AUTOSAR XML (schema 4-2-2)
package /ComponentTypes
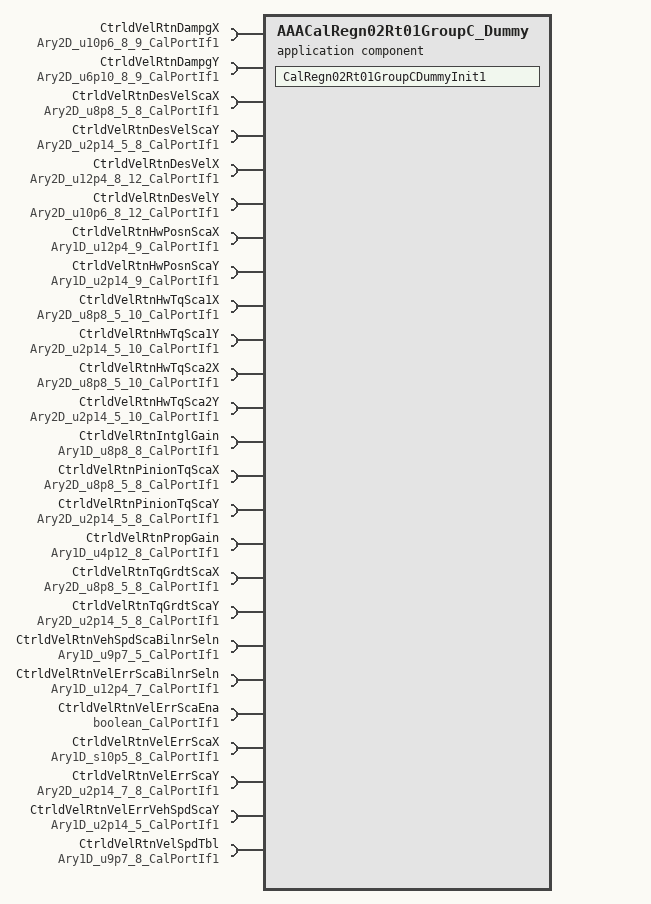
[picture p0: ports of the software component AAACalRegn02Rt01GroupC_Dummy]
  application sw component type AAACalRegn02Rt01GroupC_Dummy
    25 x require port:
      CtrldVelRtnDampgX: parameter-require-com-spec{init-value=[[0, 8960, 10560, 12160, 13760, 15360, 18560, 21760, 24960], [0, 8960, 10560, 12160, 13760, 15360, 18560, 21760, 24960], [0, 8960, 10560, 12160, 13760, 15360, 18560, 21760, 24960], [0, 8960, 10560, 12160, 13760, 15360, 18560, 21760, 24960], [0, 8960, 10560, 12160, 13760, 15360, 18560, 21760, 24960], [0, 16000, 17600, 19200, 20800, 22400, 25600, 28800, 32000], [0, 20608, 22208, 23808, 25408, 27008, 30208, 33408, 36608], [0, 26112, 27712, 29312, 30912, 32512, 35712, 38912, 42112]], parameter=Ary2D}, required-interface=Ary2D_u10p6_8_9_CalPortIf1
      CtrldVelRtnDampgY: parameter-require-com-spec{init-value=[9 x 0, 9 x 0, 9 x 0, 9 x 0, [0, 0, 1037, 4355, 9735, 16396, 33177, 33177, 33177], [0, 0, 1152, 4839, 10817, 18218, 36863, 36863, 36863], [0, 0, 1152, 4839, 10817, 18218, 36863, 36863, 36863], [0, 0, 1152, 4839, 10817, 18218, 36863, 36863, 36863]], parameter=Ary2D}, required-interface=Ary2D_u6p10_8_9_CalPortIf1
      CtrldVelRtnDesVelScaX: parameter-require-com-spec{init-value=5 x [0, 384, 512, 640, 768, 896, 1024, 2560], parameter=Ary2D}, required-interface=Ary2D_u8p8_5_8_CalPortIf1
      CtrldVelRtnDesVelScaY: parameter-require-com-spec{init-value=5 x [16384, 16384, 16384, 16384, 0, 0, 0, 0], parameter=Ary2D}, required-interface=Ary2D_u2p14_5_8_CalPortIf1
      CtrldVelRtnDesVelX: parameter-require-com-spec{init-value=8 x [0, 261, 451, 776, 994, 1220, 1441, 1767, 7200, 7216, 7232, 7248], parameter=Ary2D}, required-interface=Ary2D_u12p4_8_12_CalPortIf1
      CtrldVelRtnDesVelY: parameter-require-com-spec{init-value=[12 x 0, [0, 1788, 3385, 5353, 6805, 8089, 8953, 9259, 9259, 9259, 9259, 9259], [0, 2446, 4630, 7323, 9309, 11066, 12247, 12666, 12666, 12666, 12666, 12666], [0, 3090, 5849, 9249, 11759, 13978, 15470, 16000, 16000, 16000, 16000, 16000], [0, 3708, 7019, 11099, 14111, 16774, 18564, 19200, 19200, 19200, 19200, 19200], [0, 5340, 10108, 15983, 20320, 24155, 26732, 27648, 27648, 27648, 27648, 27648], [0, 6408, 12130, 19180, 24384, 28986, 32078, 33178, 33178, 33178, 33178, 33178], [0, 7306, 13828, 21865, 27798, 33044, 36569, 37823, 37823, 37823, 37823, 37823]], parameter=Ary2D}, required-interface=Ary2D_u10p6_8_12_CalPortIf1
      CtrldVelRtnHwPosnScaX: parameter-require-com-spec{init-value=[0, 160, 320, 640, 656, 1440, 2880, 5760, 16000], parameter=Ary1D}, required-interface=Ary1D_u12p4_9_CalPortIf1
      CtrldVelRtnHwPosnScaY: parameter-require-com-spec=Ary1D, required-interface=Ary1D_u2p14_9_CalPortIf1
      CtrldVelRtnHwTqSca1X: parameter-require-com-spec{init-value=5 x [0, 102, 128, 154, 182, 337, 412, 521, 640, 2048], parameter=Ary2D}, required-interface=Ary2D_u8p8_5_10_CalPortIf1
      CtrldVelRtnHwTqSca1Y: parameter-require-com-spec{init-value=5 x [16384, 16384, 16071, 15540, 14495, 9349, 6704, 3116, 0, 0], parameter=Ary2D}, required-interface=Ary2D_u2p14_5_10_CalPortIf1
      CtrldVelRtnHwTqSca2X: parameter-require-com-spec{init-value=5 x [0, 102, 128, 154, 182, 337, 412, 521, 640, 2048], parameter=Ary2D}, required-interface=Ary2D_u8p8_5_10_CalPortIf1
      CtrldVelRtnHwTqSca2Y: parameter-require-com-spec{init-value=5 x [16384, 16384, 16071, 15540, 14495, 9349, 6704, 3116, 0, 0], parameter=Ary2D}, required-interface=Ary2D_u2p14_5_10_CalPortIf1
      CtrldVelRtnIntglGain: parameter-require-com-spec{init-value=[0, 38, 38, 51, 64, 64, 64, 64], parameter=Ary1D}, required-interface=Ary1D_u8p8_8_CalPortIf1
      CtrldVelRtnPinionTqScaX: parameter-require-com-spec{init-value=5 x [0, 384, 512, 640, 768, 896, 1024, 2560], parameter=Ary2D}, required-interface=Ary2D_u8p8_5_8_CalPortIf1
      CtrldVelRtnPinionTqScaY: parameter-require-com-spec{init-value=[[16384, 16384, 16384, 9830, 0, 0, 0, 0], [16384, 16384, 16384, 9830, 0, 0, 0, 0], [16384, 16384, 16384, 9830, 0, 0, 0, 0], 8 x 16384, 8 x 16384], parameter=Ary2D}, required-interface=Ary2D_u2p14_5_8_CalPortIf1
      CtrldVelRtnPropGain: parameter-require-com-spec{init-value=[0, 82, 82, 205, 492, 492, 492, 492], parameter=Ary1D}, required-interface=Ary1D_u4p12_8_CalPortIf1
      CtrldVelRtnTqGrdtScaX: parameter-require-com-spec{init-value=5 x [0, 5120, 6400, 7680, 8960, 10240, 11520, 12800], parameter=Ary2D}, required-interface=Ary2D_u8p8_5_8_CalPortIf1
      CtrldVelRtnTqGrdtScaY: parameter-require-com-spec{init-value=[[16384, 16384, 13107, 8192, 4915, 4915, 4915, 4915], [16384, 16384, 13107, 8192, 4915, 4915, 4915, 4915], [16384, 16384, 13107, 8192, 4915, 4915, 4915, 4915], [16384, 16384, 13107, 11469, 6554, 6554, 6554, 6554], [16384, 16384, 13107, 11469, 6554, 6554, 6554, 6554]], parameter=Ary2D}, required-interface=Ary2D_u2p14_5_8_CalPortIf1
      CtrldVelRtnVehSpdScaBilnrSeln: parameter-require-com-spec{init-value=[0, 1280, 3840, 6400, 10240], parameter=Ary1D}, required-interface=Ary1D_u9p7_5_CalPortIf1
      CtrldVelRtnVelErrScaBilnrSeln: parameter-require-com-spec{init-value=[0, 160, 320, 480, 800, 1280, 7200], parameter=Ary1D}, required-interface=Ary1D_u12p4_7_CalPortIf1
      CtrldVelRtnVelErrScaEna: parameter-require-com-spec{init-value=0, parameter=Logl}, required-interface=boolean_CalPortIf1
      CtrldVelRtnVelErrScaX: parameter-require-com-spec{init-value=[-6400, 0, 640, 1600, 3200, 6400, 8000, 25600], parameter=Ary1D}, required-interface=Ary1D_s10p5_8_CalPortIf1
      CtrldVelRtnVelErrScaY: parameter-require-com-spec{init-value=[8 x 16384, [16384, 16384, 13107, 8192, 4915, 8192, 11469, 16384], [16384, 16384, 13107, 8192, 4915, 4915, 8192, 16384], [16384, 16384, 13107, 8192, 4915, 4915, 8192, 16384], [16384, 16384, 13107, 13107, 8192, 8192, 8192, 16384], 8 x 16384, 8 x 16384], parameter=Ary2D}, required-interface=Ary2D_u2p14_7_8_CalPortIf1
      CtrldVelRtnVelErrVehSpdScaY: parameter-require-com-spec{init-value=[16384, 16384, 16384, 11469, 11469], parameter=Ary1D}, required-interface=Ary1D_u2p14_5_CalPortIf1
      CtrldVelRtnVelSpdTbl: parameter-require-com-spec{init-value=[0, 320, 640, 2560, 3840, 6400, 7680, 10240], parameter=Ary1D}, required-interface=Ary1D_u9p7_8_CalPortIf1
    behavior AAACalRegn02Rt01GroupC_Dummy_InternalBehavior: supports-multiple-instantiation=true
      init event AAACalRegn02Rt01GroupC_Dummy_InitEvent: start-on-event=CalRegn02Rt01GroupCDummyInit1
      runnable CalRegn02Rt01GroupCDummyInit1
  swc implementation AAACalRegn02Rt00GroupC_Dummy_Implementation: behavior=AAACalRegn02Rt01GroupC_Dummy_InternalBehavior
    code-descriptors:
      code Default: artifact-descriptors=autosar-engineering-object={short-label=Default, category=SWSRC}
